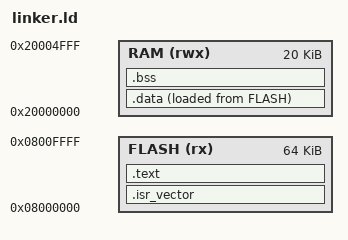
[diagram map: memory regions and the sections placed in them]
/* STM32F103C8T6: 64 KiB internal flash, 20 KiB SRAM. */
ENTRY(Reset_Handler)

MEMORY {
    FLASH (rx)  : ORIGIN = 0x08000000, LENGTH = 64K
    RAM   (rwx) : ORIGIN = 0x20000000, LENGTH = 20K
}

_estack = ORIGIN(RAM) + LENGTH(RAM);

SECTIONS {
    .isr_vector : { KEEP(*(.isr_vector)) } > FLASH
    .text : { *(.text*) *(.rodata*) } > FLASH
    . = ALIGN(4);
    .data : {
        _sdata = .;
        *(.data*)
        . = ALIGN(4);
        _edata = .;
    } > RAM AT > FLASH
    _sidata = LOADADDR(.data);
    .bss (NOLOAD) : {
        _sbss = .;
        *(.bss*) *(COMMON)
        . = ALIGN(4);
        _ebss = .;
    } > RAM
    /DISCARD/ : { *(.comment*) *(.note*) }
}
